# GD32EPRT register map
File version: 1.0
CPU: CM33 r0p4, little endian, MPU, FPU, 4 interrupt priority bits
Registers are 32-bit, read-write, reset 0x0 unless marked. A register's access mark holds for its fields unless they carry their own. Offsets are from the block's base; [hi:lo] are bit positions; {n}, {i} and the like mark numbered series.

## SQPI — Serial/Quad Parallel Interface
Base 0xA0001000
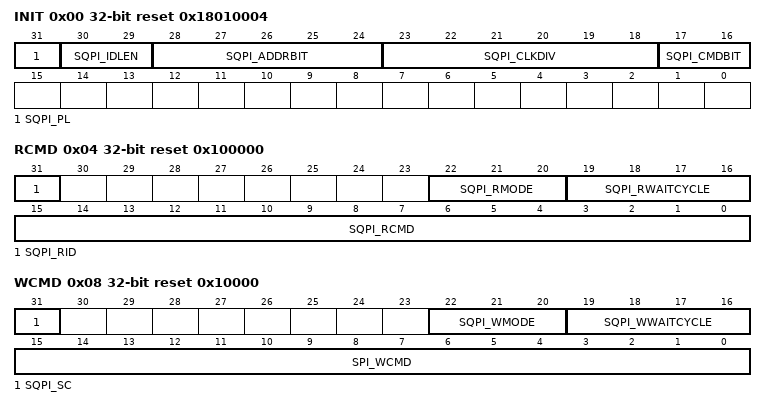
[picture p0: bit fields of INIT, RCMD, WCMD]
0x00 INIT reset 0x18010004 — SQPI Initial Register
  [31] SQPI_PL — Read data sample polarity.
  [30:29] SQPI_IDLEN — SQPI controller external memory ID length
  [28:24] SQPI_ADDRBIT — Bit number of SPI PSRAM address phase.
  [23:18] SQPI_CLKDIV — Clock divider for SQPI output clock
  [17:16] SQPI_CMDBIT — Bit number of SQPI controller command phase
0x04 RCMD reset 0x100000 — SQPI Read Command Register
  [31] SQPI_RID — Send read ID command
  [22:20] SQPI_RMODE — SQPI controller read command mode
  [19:16] SQPI_RWAITCYCLE — SQPI read command waitcycle number after address phase
  [15:0] SQPI_RCMD — SQPI read command for AHB read transfer
0x08 WCMD reset 0x10000 — Write Command Register
  [31] SQPI_SC — Send special command
  [22:20] SQPI_WMODE — SQPI controller write command mode
  [19:16] SQPI_WWAITCYCLE — SQPI write command waitcycle number after address phase
  [15:0] SPI_WCMD — SQPI write command for AHB write transfer
0x0C IDL ro — ID Low Register
  [31:0] SQPI_IDL — ID Low Data saved for SQPI Read ID Command
0x10 IDH ro — ID High Register
  [31:0] SQPI_IDH — ID High Data saved for SQPI read ID command

## TIMER5 — Basic-timers
Base 0x40001000
Same registers: TIMER6 0x40001400
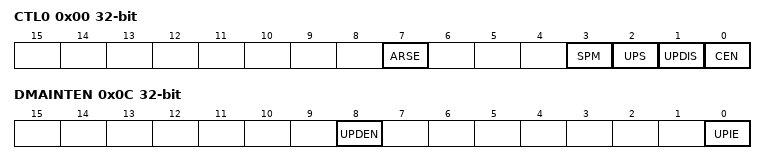
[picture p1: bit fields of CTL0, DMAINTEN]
0x00 CTL0 — control register 0
  [7] ARSE — Auto-reload shadow enable
  [3] SPM — Single pulse mode
  [2] UPS — Update source
  [1] UPDIS — Update disable
  [0] CEN — Counter enable
0x04 CTL1 — control register 1
  [6:4] MMC — Master mode control
0x0C DMAINTEN — DMA/Interrupt enable register
  [8] UPDEN — Update DMA request enable
  [0] UPIE — Update interrupt enable
0x10 INTF — Interrupt flag register
  [0] UPIF — Update interrupt flag
0x14 SWEVG wo — event generation register
  [0] UPG — Update generation
0x24 CNT — Counter register
  [15:0] CNT — Low counter value
0x28 PSC — Prescaler register
  [15:0] PSC — Prescaler value of the counter clock
0x2C CAR — Counter auto reload register
  [15:0] CARL — Counter auto reload value

## USBD — Universal serial bus full-speed device interface
Base 0x40005C00
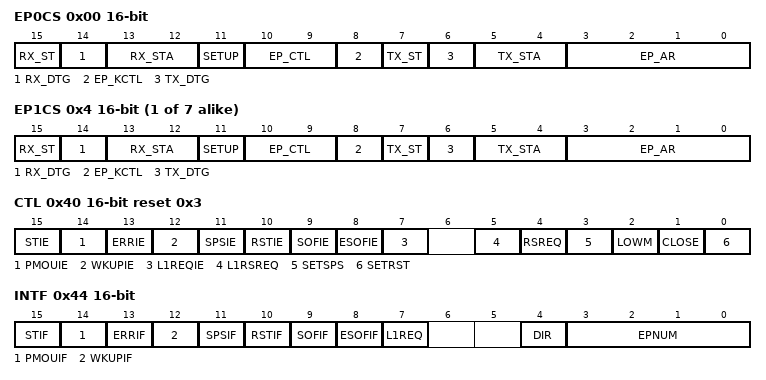
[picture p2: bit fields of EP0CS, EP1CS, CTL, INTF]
0x00 EP0CS 16-bit — endpoint 0 register
  [15] RX_ST — Correct transfer for reception
  [14] RX_DTG — Data Toggle, for reception transfers
  [13:12] RX_STA — Status bits, for reception transfers
  [11] SETUP — Setup transaction completed
  [10:9] EP_CTL — Endpoint type
  [8] EP_KCTL — Endpoint kind
  [7] TX_ST — Correct Transfer for transmission
  [6] TX_DTG — Data PID Toggle, for transmission transfers
  [5:4] TX_STA — Status bits, for transmission transfers
  [3:0] EP_AR — Endpoint address
{0x0+4i} EP{i}CS 16-bit (i=1..7) — endpoint {i} register
  [15] RX_ST — Correct transfer for reception
  [14] RX_DTG — Data Toggle, for reception transfers
  [13:12] RX_STA — Status bits, for reception transfers
  [11] SETUP — Setup transaction completed
  [10:9] EP_CTL — Endpoint type
  [8] EP_KCTL — Endpoint kind
  [7] TX_ST — Correct Transfer for transmission
  [6] TX_DTG — Data Toggle, for transmission transfers
  [5:4] TX_STA — Status bits, for transmission transfers
  [3:0] EP_AR — Endpoint address
0x40 CTL 16-bit reset 0x3 — control register
  [15] STIE — Successful transfer interrupt enable
  [14] PMOUIE — Packet memory area over / underrun interrupt enable
  [13] ERRIE — Error interrupt mask
  [12] WKUPIE — Wakeup interrupt enable
  [11] SPSIE — Suspend mode interrupt mask
  [10] RSTIE — USB reset interrupt mask
  [9] SOFIE — Start of frame interrupt mask
  [8] ESOFIE — Expected start of frame interrupt enable
  [7] L1REQIE — LPM L1 state request interrupt enable
  [5] L1RSREQ — LPM L1 resume request
  [4] RSREQ — Resume request
  [3] SETSPS — Set suspend
  [2] LOWM — Low-power mode
  [1] CLOSE — Close state
  [0] SETRST — Set reset
0x44 INTF 16-bit — interrupt flag register
  [15] STIF — Successful transfer interrupt flag
  [14] PMOUIF — Packet memory area over / underrun interrupt flag
  [13] ERRIF — Error interrupt flag
  [12] WKUPIF — Wakeup interrupt flag
  [11] SPSIF — Suspend mode interrupt flag
  [10] RSTIF — reset interrupt flag
  [9] SOFIF — start of frame interrupt flag
  [8] ESOFIF — Expected start of frame interrupt flag
  [7] L1REQ — LPM L1 transaction is successful
  [4] DIR — Direction of transaction
  [3:0] EPNUM — Endpoint Identifier
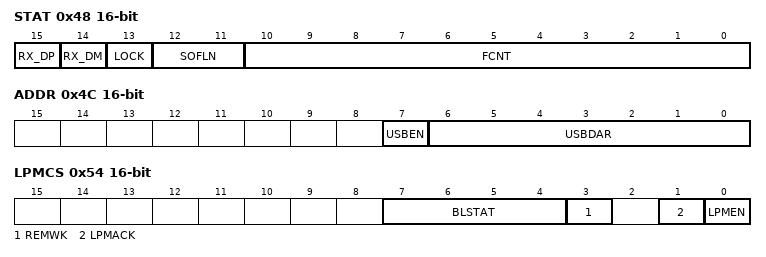
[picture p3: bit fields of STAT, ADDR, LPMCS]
0x48 STAT 16-bit ro — Status register
  [15] RX_DP — Receive data + line status
  [14] RX_DM — Receive data - line status
  [13] LOCK — Locked the USB
  [12:11] SOFLN — Lost SOF number
  [10:0] FCNT — Frame number counter
0x4C ADDR 16-bit — device address register
  [7] USBEN — USB device enable
  [6:0] USBDAR — Device address
0x50 BADDR 16-bit — Buffer address register
  [15:3] BAR — Buffer address
0x54 LPMCS 16-bit — USB LPM control and status register
  [7:4] BLSTAT — bLinkState value
  [3] REMWK — bRemoteWake value
  [1] LPMACK — LPM token acknowledge enable
  [0] LPMEN — LPM support enable
